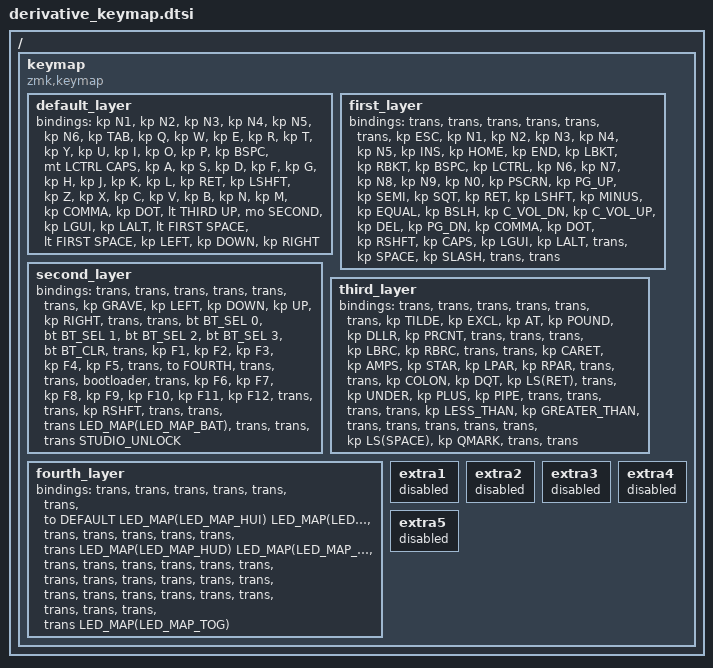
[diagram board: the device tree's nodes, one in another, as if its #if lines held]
/*
 * Shared keymap for the derivative keyboard.
 *
 * Included by both:
 *   - the standalone board build (derivative-rev-a.keymap), where the board
 *     itself is the HID central, and
 *   - the dongle central build (derivative_dongle shield), where a XIAO
 *     nRF52840 holds the keymap and the derivative acts as a split peripheral.
 *
 * Keep this the single source of truth for layers/bindings. Features that only
 * exist on one side are guarded so the same file compiles in both builds:
 *   - STUDIO_UNLOCK: real behavior when ZMK Studio is enabled, else transparent.
 *   - LED_MAP(x):    real led_map behavior when the RGB strip is present
 *                    (standalone / peripheral), else transparent (dongle has no
 *                    strip). NOTE: in dongle mode keymap-driven LED changes do
 *                    not yet reach the peripheral's strip -- see README.
 */

#include <behaviors.dtsi>
#include <dt-bindings/zmk/keys.h>
#include <dt-bindings/zmk/bt.h>

#ifdef CONFIG_ZMK_STUDIO
#include <dt-bindings/zmk/studio.h>
#define STUDIO_UNLOCK &studio_unlock
#else
#define STUDIO_UNLOCK &trans
#endif

#ifdef CONFIG_ZMK_LED_MAP
#include <dt-bindings/zmk/led_map.h>
#define LED_MAP(x) &led_map x
#else
#define LED_MAP(x) &trans
#endif

#define DEFAULT 0
#define FIRST   1
#define SECOND  2
#define THIRD   3
#define FOURTH  4

/ {
    keymap {
        compatible = "zmk,keymap";

        default_layer {

            // | 1 | 2 | 3 | 4 | 5 | 6 |
            // | TAB | Q | W | E | R | T | Y | U | I | O | P | BSPC |
            // | CAPS/CTRL | A | S | D | F | G | H | J | K | L | ENTER |
            // | LSHIFT | Z | X | C | V | B | N | M | , | . | LT(3,UP) |
            // | MO(2) | WIN | ALT | LT(1,SPACE) | LT(1,SPACE) | LEFT | DOWN | RIGHT |
            bindings = <
                &kp N1  &kp N2  &kp N3  &kp N4  &kp N5  &kp N6
                &kp TAB  &kp Q  &kp W  &kp E  &kp R  &kp T  &kp Y  &kp U  &kp I  &kp O  &kp P  &kp BSPC
                &mt LCTRL CAPS  &kp A  &kp S  &kp D  &kp F  &kp G  &kp H  &kp J  &kp K  &kp L  &kp RET
                &kp LSHFT  &kp Z  &kp X  &kp C  &kp V  &kp B  &kp N  &kp M  &kp COMMA  &kp DOT  &lt THIRD UP
                &mo SECOND  &kp LGUI  &kp LALT  &lt FIRST SPACE  &lt FIRST SPACE  &kp LEFT  &kp DOWN  &kp RIGHT
            >;
        };

        first_layer {

            // | --- | --- | --- | --- | --- | --- |
            // | ESC | 1 | 2 | 3 | 4 | 5 | INS | HOME | END | [ | ] | BSPC |
            // | CTRL | 6 | 7 | 8 | 9 | 0 | PSCRN | PGUP | ; | ' | ENTER |
            // | SHIFT | - | = | \ | VOL- | VOL+ | DEL | PGDN | , | . | SHIFT |
            // | CAPS | WIN | ALT | --- | SPACE | / | --- | --- |
            bindings = <
                &trans  &trans  &trans  &trans  &trans  &trans
                &kp ESC  &kp N1  &kp N2  &kp N3  &kp N4  &kp N5  &kp INS  &kp HOME  &kp END  &kp LBKT  &kp RBKT  &kp BSPC
                &kp LCTRL  &kp N6  &kp N7  &kp N8  &kp N9  &kp N0  &kp PSCRN  &kp PG_UP  &kp SEMI  &kp SQT  &kp RET
                &kp LSHFT  &kp MINUS  &kp EQUAL  &kp BSLH  &kp C_VOL_DN  &kp C_VOL_UP  &kp DEL  &kp PG_DN  &kp COMMA  &kp DOT  &kp RSHFT
                &kp CAPS  &kp LGUI  &kp LALT  &trans  &kp SPACE  &kp SLASH  &trans  &trans
            >;
        };

        second_layer {

            // | --- | --- | --- | --- | --- | --- |
            // | ` | ← | ↓ | ↑ | → | --- | --- | BT0 | BT1 | BT2 | BT3 | CLR |
            // | --- | F1 | F2 | F3 | F4 | F5 | --- | TO(4) | --- | --- | BOOT |
            // | --- | F6 | F7 | F8 | F9 | F10 | F11 | F12 | --- | --- | SHIFT |
            // | --- | --- | --- | BAT | --- | --- | --- | studio_unlock |
            bindings = <
                &trans  &trans  &trans  &trans  &trans  &trans
                &kp GRAVE  &kp LEFT  &kp DOWN  &kp UP  &kp RIGHT  &trans  &trans  &bt BT_SEL 0  &bt BT_SEL 1  &bt BT_SEL 2  &bt BT_SEL 3  &bt BT_CLR
                &trans  &kp F1  &kp F2  &kp F3  &kp F4  &kp F5  &trans  &to FOURTH  &trans  &trans  &bootloader
                &trans  &kp F6  &kp F7  &kp F8  &kp F9  &kp F10  &kp F11  &kp F12  &trans  &trans  &kp RSHFT
                &trans  &trans  &trans  LED_MAP(LED_MAP_BAT)  &trans  &trans  &trans  STUDIO_UNLOCK
            >;
        };

        third_layer {

            // | --- | --- | --- | --- | --- | --- |
            // | ~ | ! | @ | # | $ | % | --- | --- | --- | [ | ] | --- |
            // | --- | ^ | & | * | ( | ) | --- | --- | : | " | Shift+Enter |
            // | --- | _ | + | | | --- | --- | --- | --- | < | > | --- |
            // | --- | --- | --- | --- | Shift+Space | ? | --- | --- |
            bindings = <
                &trans  &trans  &trans  &trans  &trans  &trans
                &kp TILDE  &kp EXCL  &kp AT  &kp POUND  &kp DLLR  &kp PRCNT  &trans  &trans  &trans  &kp LBRC  &kp RBRC  &trans
                &trans  &kp CARET  &kp AMPS  &kp STAR  &kp LPAR  &kp RPAR  &trans  &trans  &kp COLON  &kp DQT  &kp LS(RET)
                &trans  &kp UNDER  &kp PLUS  &kp PIPE  &trans  &trans  &trans  &trans  &kp LESS_THAN  &kp GREATER_THAN  &trans
                &trans  &trans  &trans  &trans  &kp LS(SPACE)  &kp QMARK  &trans  &trans
            >;
        };

        fourth_layer {

            // Per-key LED controls
            // | --- | --- | --- | --- | --- | --- |
            // | TO(0) | HUI | SAI | SPI | BRI | EFF | SUB_EFF | --- | --- | --- | --- | --- |
            // | --- | HUD | SAD | SPD | BRD | EFR | SUB_EFR | --- | --- | --- | --- |
            // | --- | --- | --- | --- | --- | --- | --- | --- | --- | --- | --- |
            // | --- | --- | --- | --- | --- | --- | --- | TOG |
            bindings = <
                &trans  &trans  &trans  &trans  &trans  &trans
                &to DEFAULT  LED_MAP(LED_MAP_HUI)  LED_MAP(LED_MAP_SAI)  LED_MAP(LED_MAP_SPI)  LED_MAP(LED_MAP_BRI)  LED_MAP(LED_MAP_EFF)  LED_MAP(LED_MAP_SUB_EFF)  &trans  &trans  &trans  &trans  &trans
                &trans  LED_MAP(LED_MAP_HUD)  LED_MAP(LED_MAP_SAD)  LED_MAP(LED_MAP_SPD)  LED_MAP(LED_MAP_BRD)  LED_MAP(LED_MAP_EFR)  LED_MAP(LED_MAP_SUB_EFR)  &trans  &trans  &trans  &trans
                &trans  &trans  &trans  &trans  &trans  &trans  &trans  &trans  &trans  &trans  &trans
                &trans  &trans  &trans  &trans  &trans  &trans  &trans  LED_MAP(LED_MAP_TOG)
            >;
        };

        extra1 {
            status = "reserved";
        };

        extra2 {
            status = "reserved";
        };

        extra3 {
            status = "reserved";
        };

        extra4 {
            status = "reserved";
        };

        extra5 {
            status = "reserved";
        };
    };
};
